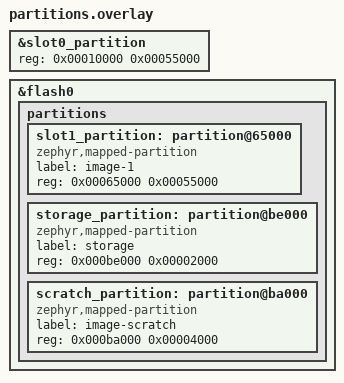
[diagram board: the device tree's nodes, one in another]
/* SPDX-License-Identifier: Apache-2.0 */
/* Keep MBR, the factory UF2 loader and its settings outside the OTA regions. */
&slot0_partition {
	reg = <0x00010000 0x00055000>;
};

&flash0 {
	partitions {
		/delete-node/ partition@76000;
		/delete-node/ partition@dc000;
		slot1_partition: partition@65000 {
			compatible = "zephyr,mapped-partition";
			label = "image-1";
			reg = <0x00065000 0x00055000>;
		};
		storage_partition: partition@be000 {
			compatible = "zephyr,mapped-partition";
			label = "storage";
			reg = <0x000be000 0x00002000>;
		};
		scratch_partition: partition@ba000 {
			compatible = "zephyr,mapped-partition";
			label = "image-scratch";
			reg = <0x000ba000 0x00004000>;
		};
	};
};
